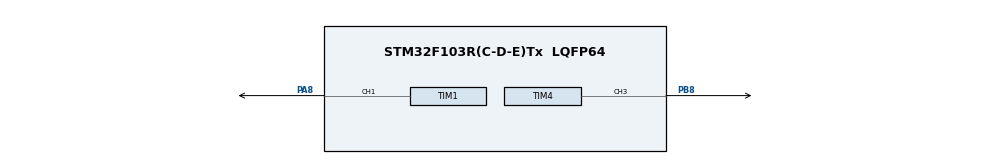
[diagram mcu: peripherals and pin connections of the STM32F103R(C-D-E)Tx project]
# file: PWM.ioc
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Mcu.Family=STM32F1
Mcu.Name=STM32F103R(C-D-E)Tx
Mcu.Package=LQFP64
NVIC.PriorityGroup=NVIC_PRIORITYGROUP_4
PA8.Signal=S_TIM1_CH1
PB8.Signal=S_TIM4_CH3
PD0-OSC_IN.Mode=HSE-External-Oscillator
PD0-OSC_IN.Signal=RCC_OSC_IN
PD1-OSC_OUT.Mode=HSE-External-Oscillator
PD1-OSC_OUT.Signal=RCC_OSC_OUT
ProjectManager.TargetToolchain=EWARM
RCC.APB1Freq_Value=8000000
RCC.APB2Freq_Value=8000000
SH.S_TIM1_CH1.0=TIM1_CH1,PWM Generation1 CH1
SH.S_TIM4_CH3.0=TIM4_CH3,PWM Generation3 CH3
TIM1.Period=255
TIM1.Prescaler=0
TIM1.TIM_MasterOutputTrigger=TIM_TRGO_RESET
TIM1.TIM_MasterSlaveMode=TIM_MASTERSLAVEMODE_DISABLE
TIM4.Channel-PWM\ Generation3\ CH3=TIM_CHANNEL_3
TIM4.Period=255
TIM4.Prescaler=0
VP_TIM1_VS_ClockSourceINT.Mode=Internal
VP_TIM4_VS_ClockSourceINT.Mode=Internal
board=PWM

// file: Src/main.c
/**
  ******************************************************************************
  * File Name          : main.c
  * Description        : Main program body
  ******************************************************************************
  *
  * COPYRIGHT(c) 2016 STMicroelectronics
  *
  * Redistribution and use in source and binary forms, with or without modification,
  * are permitted provided that the following conditions are met:
  *   1. Redistributions of source code must retain the above copyright notice,
  *      this list of conditions and the following disclaimer.
  *   2. Redistributions in binary form must reproduce the above copyright notice,
  *      this list of conditions and the following disclaimer in the documentation
  *      and/or other materials provided with the distribution.
  *   3. Neither the name of STMicroelectronics nor the names of its contributors
  *      may be used to endorse or promote products derived from this software
  *      without specific prior written permission.
  *
  * THIS SOFTWARE IS PROVIDED BY THE COPYRIGHT HOLDERS AND CONTRIBUTORS "AS IS"
  * AND ANY EXPRESS OR IMPLIED WARRANTIES, INCLUDING, BUT NOT LIMITED TO, THE
  * IMPLIED WARRANTIES OF MERCHANTABILITY AND FITNESS FOR A PARTICULAR PURPOSE ARE
  * DISCLAIMED. IN NO EVENT SHALL THE COPYRIGHT HOLDER OR CONTRIBUTORS BE LIABLE
  * FOR ANY DIRECT, INDIRECT, INCIDENTAL, SPECIAL, EXEMPLARY, OR CONSEQUENTIAL
  * DAMAGES (INCLUDING, BUT NOT LIMITED TO, PROCUREMENT OF SUBSTITUTE GOODS OR
  * SERVICES; LOSS OF USE, DATA, OR PROFITS; OR BUSINESS INTERRUPTION) HOWEVER
  * CAUSED AND ON ANY THEORY OF LIABILITY, WHETHER IN CONTRACT, STRICT LIABILITY,
  * OR TORT (INCLUDING NEGLIGENCE OR OTHERWISE) ARISING IN ANY WAY OUT OF THE USE
  * OF THIS SOFTWARE, EVEN IF ADVISED OF THE POSSIBILITY OF SUCH DAMAGE.
  *
  ******************************************************************************
  */
#include "stm32f1xx_hal.h"

TIM_HandleTypeDef htim1;
TIM_HandleTypeDef htim4;

/* USER CODE BEGIN PV */
/* Private variables ---------------------------------------------------------*/

/* USER CODE END PV */

void SystemClock_Config(void);
static void MX_GPIO_Init(void);
static void MX_TIM1_Init(void);
static void MX_TIM4_Init(void);

/* USER CODE BEGIN PFP */
/* Private function prototypes -----------------------------------------------*/

/* USER CODE END PFP */

int main(void)
{

  /* MCU Configuration----------------------------------------------------------*/

  /* Reset of all peripherals, Initializes the Flash interface and the Systick. */
  HAL_Init();

  /* Configure the system clock */
  SystemClock_Config();

  /* Initialize all configured peripherals */
  MX_GPIO_Init();
  MX_TIM1_Init();
  MX_TIM4_Init();

  /* USER CODE BEGIN 2 */

  HAL_TIM_PWM_Start(&htim1, TIM_CHANNEL_1);
  HAL_TIM_PWM_Start(&htim4, TIM_CHANNEL_3);

  /* USER CODE END 2 */

  /* Infinite loop */
  /* USER CODE BEGIN WHILE */
  while (1)
  {
    __HAL_TIM_SET_COMPARE(&htim1, TIM_CHANNEL_1, 127);
    __HAL_TIM_SET_COMPARE(&htim4, TIM_CHANNEL_3, 32);

  /* USER CODE END WHILE */

  }
}

/** System Clock Configuration
*/
void SystemClock_Config(void)
{

  RCC_OscInitTypeDef RCC_OscInitStruct;
  RCC_ClkInitTypeDef RCC_ClkInitStruct;

  RCC_OscInitStruct.OscillatorType = RCC_OSCILLATORTYPE_HSI;
  RCC_OscInitStruct.HSIState = RCC_HSI_ON;
  RCC_OscInitStruct.HSICalibrationValue = 16;
  RCC_OscInitStruct.PLL.PLLState = RCC_PLL_NONE;
  HAL_RCC_OscConfig(&RCC_OscInitStruct);

  RCC_ClkInitStruct.ClockType = RCC_CLOCKTYPE_SYSCLK;
  RCC_ClkInitStruct.SYSCLKSource = RCC_SYSCLKSOURCE_HSI;
  RCC_ClkInitStruct.AHBCLKDivider = RCC_SYSCLK_DIV1;
  RCC_ClkInitStruct.APB1CLKDivider = RCC_HCLK_DIV1;
  RCC_ClkInitStruct.APB2CLKDivider = RCC_HCLK_DIV1;
  HAL_RCC_ClockConfig(&RCC_ClkInitStruct, FLASH_LATENCY_0);

  HAL_SYSTICK_Config(HAL_RCC_GetHCLKFreq()/1000);

  HAL_SYSTICK_CLKSourceConfig(SYSTICK_CLKSOURCE_HCLK);

  /* SysTick_IRQn interrupt configuration */
  HAL_NVIC_SetPriority(SysTick_IRQn, 0, 0);
}

/* TIM1 init function */
void MX_TIM1_Init(void)
{

  TIM_ClockConfigTypeDef sClockSourceConfig;
  TIM_MasterConfigTypeDef sMasterConfig;
  TIM_BreakDeadTimeConfigTypeDef sBreakDeadTimeConfig;
  TIM_OC_InitTypeDef sConfigOC;

  htim1.Instance = TIM1;
  htim1.Init.Prescaler = 0;
  htim1.Init.CounterMode = TIM_COUNTERMODE_UP;
  htim1.Init.Period = 255;
  htim1.Init.ClockDivision = TIM_CLOCKDIVISION_DIV1;
  htim1.Init.RepetitionCounter = 0;
  HAL_TIM_Base_Init(&htim1);

  sClockSourceConfig.ClockSource = TIM_CLOCKSOURCE_INTERNAL;
  HAL_TIM_ConfigClockSource(&htim1, &sClockSourceConfig);

  HAL_TIM_PWM_Init(&htim1);

  sMasterConfig.MasterOutputTrigger = TIM_TRGO_RESET;
  sMasterConfig.MasterSlaveMode = TIM_MASTERSLAVEMODE_DISABLE;
  HAL_TIMEx_MasterConfigSynchronization(&htim1, &sMasterConfig);

  sBreakDeadTimeConfig.OffStateRunMode = TIM_OSSR_DISABLE;
  sBreakDeadTimeConfig.OffStateIDLEMode = TIM_OSSI_DISABLE;
  sBreakDeadTimeConfig.LockLevel = TIM_LOCKLEVEL_OFF;
  sBreakDeadTimeConfig.DeadTime = 0;
  sBreakDeadTimeConfig.BreakState = TIM_BREAK_DISABLE;
  sBreakDeadTimeConfig.BreakPolarity = TIM_BREAKPOLARITY_HIGH;
  sBreakDeadTimeConfig.AutomaticOutput = TIM_AUTOMATICOUTPUT_DISABLE;
  HAL_TIMEx_ConfigBreakDeadTime(&htim1, &sBreakDeadTimeConfig);

  sConfigOC.OCMode = TIM_OCMODE_PWM1;
  sConfigOC.Pulse = 0;
  sConfigOC.OCPolarity = TIM_OCPOLARITY_HIGH;
  sConfigOC.OCNPolarity = TIM_OCNPOLARITY_HIGH;
  sConfigOC.OCFastMode = TIM_OCFAST_DISABLE;
  sConfigOC.OCIdleState = TIM_OCIDLESTATE_RESET;
  sConfigOC.OCNIdleState = TIM_OCNIDLESTATE_RESET;
  HAL_TIM_PWM_ConfigChannel(&htim1, &sConfigOC, TIM_CHANNEL_1);

}

/* TIM4 init function */
void MX_TIM4_Init(void)
{

  TIM_ClockConfigTypeDef sClockSourceConfig;
  TIM_MasterConfigTypeDef sMasterConfig;
  TIM_OC_InitTypeDef sConfigOC;

  htim4.Instance = TIM4;
  htim4.Init.Prescaler = 0;
  htim4.Init.CounterMode = TIM_COUNTERMODE_UP;
  htim4.Init.Period = 255;
  htim4.Init.ClockDivision = TIM_CLOCKDIVISION_DIV1;
  HAL_TIM_Base_Init(&htim4);

  sClockSourceConfig.ClockSource = TIM_CLOCKSOURCE_INTERNAL;
  HAL_TIM_ConfigClockSource(&htim4, &sClockSourceConfig);

  HAL_TIM_PWM_Init(&htim4);

  sMasterConfig.MasterOutputTrigger = TIM_TRGO_RESET;
  sMasterConfig.MasterSlaveMode = TIM_MASTERSLAVEMODE_DISABLE;
  HAL_TIMEx_MasterConfigSynchronization(&htim4, &sMasterConfig);

  sConfigOC.OCMode = TIM_OCMODE_PWM1;
  sConfigOC.Pulse = 0;
  sConfigOC.OCPolarity = TIM_OCPOLARITY_HIGH;
  sConfigOC.OCFastMode = TIM_OCFAST_DISABLE;
  HAL_TIM_PWM_ConfigChannel(&htim4, &sConfigOC, TIM_CHANNEL_3);

}

/** Configure pins as
        * Analog
        * Input
        * Output
        * EVENT_OUT
        * EXTI
*/
void MX_GPIO_Init(void)
{

  /* GPIO Ports Clock Enable */
  __GPIOD_CLK_ENABLE();
  __GPIOA_CLK_ENABLE();
  __GPIOB_CLK_ENABLE();

}

/************************ (C) COPYRIGHT STMicroelectronics *****END OF FILE****/
